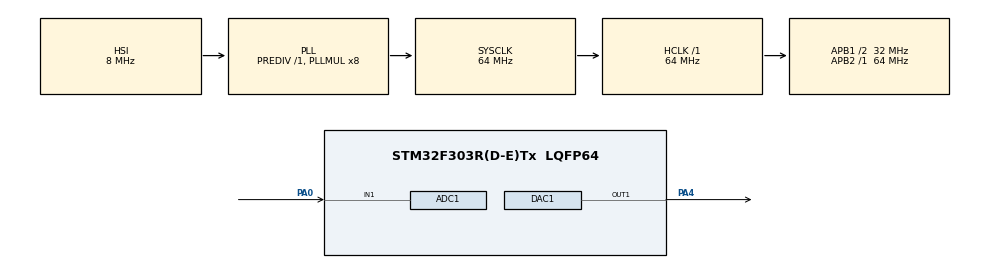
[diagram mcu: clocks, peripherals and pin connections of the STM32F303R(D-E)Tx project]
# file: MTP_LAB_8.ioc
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ADC1.Channel-5\#ChannelRegularConversion=ADC_CHANNEL_1
ADC1.Channel-6\#ChannelRegularConversion=ADC_CHANNEL_TEMPSENSOR
ADC1.Channel-7\#ChannelRegularConversion=ADC_CHANNEL_VREFINT
ADC1.ClockPrescaler=ADC_CLOCK_ASYNC_DIV1
ADC1.ContinuousConvMode=DISABLE
ADC1.DMAContinuousRequests=ENABLE
ADC1.EOCSelection=ADC_EOC_SINGLE_CONV
ADC1.EnableAnalogWatchDog1=false
ADC1.EnableInjectedConversion=DISABLE
ADC1.EnableRegularConversion=ENABLE
ADC1.ExternalTrigConv=ADC_EXTERNALTRIGCONV_T6_TRGO
ADC1.NbrOfConversion=3
ADC1.NbrOfConversionFlag=1
ADC1.Offset-5\#ChannelRegularConversion=0
ADC1.Offset-6\#ChannelRegularConversion=0
ADC1.Offset-7\#ChannelRegularConversion=0
ADC1.OffsetNumber-5\#ChannelRegularConversion=ADC_OFFSET_NONE
ADC1.OffsetNumber-6\#ChannelRegularConversion=ADC_OFFSET_NONE
ADC1.OffsetNumber-7\#ChannelRegularConversion=ADC_OFFSET_NONE
ADC1.Rank-5\#ChannelRegularConversion=1
ADC1.Rank-6\#ChannelRegularConversion=2
ADC1.Rank-7\#ChannelRegularConversion=3
ADC1.SamplingTime-5\#ChannelRegularConversion=ADC_SAMPLETIME_7CYCLES_5
ADC1.SamplingTime-6\#ChannelRegularConversion=ADC_SAMPLETIME_181CYCLES_5
ADC1.SamplingTime-7\#ChannelRegularConversion=ADC_SAMPLETIME_181CYCLES_5
ADC1.master=1
DAC1.DAC_Trigger=DAC_TRIGGER_T2_TRGO
Dma.ADC1.0.Direction=DMA_PERIPH_TO_MEMORY
Dma.ADC1.0.Instance=DMA1_Channel1
Dma.ADC1.0.MemDataAlignment=DMA_MDATAALIGN_WORD
Dma.ADC1.0.MemInc=DMA_MINC_ENABLE
Dma.ADC1.0.Mode=DMA_CIRCULAR
Dma.ADC1.0.PeriphDataAlignment=DMA_PDATAALIGN_WORD
Dma.ADC1.0.PeriphInc=DMA_PINC_DISABLE
Dma.ADC1.0.Priority=DMA_PRIORITY_VERY_HIGH
Dma.DAC1_CH1.1.Direction=DMA_MEMORY_TO_PERIPH
Dma.DAC1_CH1.1.Instance=DMA1_Channel3
Dma.DAC1_CH1.1.MemDataAlignment=DMA_MDATAALIGN_BYTE
Dma.DAC1_CH1.1.MemInc=DMA_MINC_ENABLE
Dma.DAC1_CH1.1.Mode=DMA_CIRCULAR
Dma.DAC1_CH1.1.PeriphDataAlignment=DMA_PDATAALIGN_BYTE
Dma.DAC1_CH1.1.PeriphInc=DMA_PINC_DISABLE
Dma.DAC1_CH1.1.Priority=DMA_PRIORITY_VERY_HIGH
Dma.Request0=ADC1
Dma.Request1=DAC1_CH1
Mcu.Family=STM32F3
Mcu.Name=STM32F303R(D-E)Tx
Mcu.Package=LQFP64
NVIC.DMA1_Channel1_IRQn=true\:0\:0\:false\:false\:true\:false\:true
NVIC.DMA1_Channel3_IRQn=true\:0\:0\:false\:false\:true\:false\:true
NVIC.PriorityGroup=NVIC_PRIORITYGROUP_4
NVIC.TIM2_IRQn=true\:0\:0\:false\:false\:true\:true\:true
PA0.Mode=IN1-Single-Ended
PA0.Signal=ADC1_IN1
PA13.Mode=Serial_Wire
PA13.Signal=SYS_JTMS-SWDIO
PA14.Mode=Serial_Wire
PA14.Signal=SYS_JTCK-SWCLK
PA4.Signal=COMP_DAC11_group
ProjectManager.HeapSize=0x200
ProjectManager.StackSize=0x400
ProjectManager.TargetToolchain=STM32CubeIDE
RCC.AHBFreq_Value=64000000
RCC.APB1CLKDivider=RCC_HCLK_DIV2
RCC.APB1Freq_Value=32000000
RCC.APB1TimFreq_Value=64000000
RCC.APB2Freq_Value=64000000
RCC.APB2TimFreq_Value=64000000
RCC.CortexFreq_Value=64000000
RCC.HCLKFreq_Value=64000000
RCC.HSE_VALUE=8000000
RCC.HSI_VALUE=8000000
RCC.LSE_VALUE=32768
RCC.PLLMUL=RCC_PLL_MUL8
RCC.SYSCLKFreq_VALUE=64000000
RCC.SYSCLKSourceVirtual=RCC_SYSCLKSOURCE_PLLCLK
RCC.USBFreq_Value=64000000
SH.COMP_DAC11_group.0=DAC1_OUT1,DAC_OUT1
TIM2.Period=999
TIM2.Prescaler=6399
TIM2.TIM_MasterOutputTrigger=TIM_TRGO_UPDATE
TIM6.Period=63
TIM6.Prescaler=0
TIM6.TIM_MasterOutputTrigger=TIM_TRGO_UPDATE
VP_ADC1_TempSens_Input.Mode=IN-TempSens
VP_ADC1_Vref_Input.Mode=IN-Vrefint
VP_TIM2_VS_ClockSourceINT.Mode=Internal
VP_TIM6_VS_ClockSourceINT.Mode=Enable_Timer
board=custom

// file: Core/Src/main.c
/* USER CODE BEGIN Header */
/**
  ******************************************************************************
  * @file           : main.c
  * @brief          : Main program body
  ******************************************************************************
  * @attention
  *
  * <h2><center>&copy; Copyright (c) 2021 STMicroelectronics.
  * All rights reserved.</center></h2>
  *
  * This software component is licensed by ST under BSD 3-Clause license,
  * the "License"; You may not use this file except in compliance with the
  * License. You may obtain a copy of the License at:
  *                        opensource.org/licenses/BSD-3-Clause
  *
  ******************************************************************************
  */
/* USER CODE END Header */

#include "main.h"

/* USER CODE BEGIN Includes */
#include <math.h>
#include <stdio.h>
/* USER CODE END Includes */

/* USER CODE BEGIN PTD */
typedef union
{
	struct {
		uint32_t usCh1;
		uint32_t usTemInt;
		uint32_t usVrefInt;
	};
	uint32_t usADCall[3];
} ADCData_t;
/* USER CODE END PTD */

void SystemClock_Config(void);
static void MX_GPIO_Init(void);
static void MX_DMA_Init(void);
static void MX_ADC1_Init(void);
static void MX_DAC1_Init(void);
static void MX_TIM2_Init(void);
static void MX_TIM6_Init(void);
/* USER CODE BEGIN PFP */

#define RESOLUTION	256.0

uint8_t ubSinValues[(int)RESOLUTION];
uint8_t sindex;

ADCData_t adcData;
uint32_t vref, vcalc, vtemp;
/* USER CODE END PFP */

int main(void)
{
  /* USER CODE BEGIN 1 */
  for (uint16_t i = 0; i < (int)RESOLUTION; i++) {
	  ubSinValues[i] = (uint8_t)((sin((double)M_PI*2.0*(double)i/RESOLUTION) * (double)0.5)*(double)(RESOLUTION));
  }
  /* USER CODE END 1 */

  /* MCU Configuration--------------------------------------------------------*/

  /* Reset of all peripherals, Initializes the Flash interface and the Systick. */
  HAL_Init();

  /* Configure the system clock */
  SystemClock_Config();

  /* Initialize all configured peripherals */
  MX_GPIO_Init();
  MX_DMA_Init();
  MX_ADC1_Init();
  MX_DAC1_Init();
  MX_TIM2_Init();
  MX_TIM6_Init();
  /* USER CODE BEGIN 2 */

  LL_DMA_SetMemoryAddress(DMA1, LL_DMA_CHANNEL_1, (uint32_t)&adcData);
  LL_DMA_SetDataLength(DMA1, LL_DMA_CHANNEL_1, 3);
  LL_DMA_SetPeriphAddress(DMA1, LL_DMA_CHANNEL_1, (uint32_t)&ADC1->DR);
  LL_DMA_EnableChannel(DMA1, LL_DMA_CHANNEL_1);

  LL_ADC_EnableInternalRegulator(ADC1);
  HAL_Delay(1);

  ADC12_COMMON->CCR |= ADC_CCR_TSEN | ADC_CCR_VREFEN;
  HAL_Delay(1);

  LL_ADC_StartCalibration(ADC1, LL_ADC_SINGLE_ENDED);
  while(LL_ADC_IsCalibrationOnGoing(ADC1));

  LL_ADC_REG_StartConversion(ADC1);
  LL_ADC_Enable(ADC1);

  LL_DMA_SetMemoryAddress(DMA1, LL_DMA_CHANNEL_3, (uint32_t)ubSinValues);
  LL_DMA_SetDataLength(DMA1, LL_DMA_CHANNEL_3, RESOLUTION);
  LL_DMA_SetPeriphAddress(DMA1, LL_DMA_CHANNEL_3, (uint32_t)&DAC1->DHR8R1);
  LL_DMA_EnableChannel(DMA1, LL_DMA_CHANNEL_3);

  LL_DAC_Enable(DAC1, LL_DAC_CHANNEL_1);
  LL_DAC_EnableDMAReq(DAC1, LL_DAC_CHANNEL_1);

  LL_TIM_EnableCounter(TIM2);
  LL_TIM_EnableCounter(TIM6);

  /* USER CODE END 2 */

  /* Infinite loop */
  /* USER CODE BEGIN WHILE */
  HAL_Delay(10); // wait load data otherwise hardfault
  while (1)
  {
	  vref = __LL_ADC_CALC_VREFANALOG_VOLTAGE((uint32_t)adcData.usVrefInt, LL_ADC_RESOLUTION_12B);
	  vcalc = __LL_ADC_CALC_DATA_TO_VOLTAGE(vref, (uint32_t)adcData.usCh1, LL_ADC_RESOLUTION_12B);
	  vtemp = __LL_ADC_CALC_TEMPERATURE(vref, (uint32_t)adcData.usTemInt, LL_ADC_RESOLUTION_12B);
    /* USER CODE END WHILE */

  }
}

void SystemClock_Config(void)
{
  RCC_OscInitTypeDef RCC_OscInitStruct = {0};
  RCC_ClkInitTypeDef RCC_ClkInitStruct = {0};
  RCC_PeriphCLKInitTypeDef PeriphClkInit = {0};

  /** Initializes the CPU, AHB and APB busses clocks
  */
  RCC_OscInitStruct.OscillatorType = RCC_OSCILLATORTYPE_HSI;
  RCC_OscInitStruct.HSIState = RCC_HSI_ON;
  RCC_OscInitStruct.HSICalibrationValue = RCC_HSICALIBRATION_DEFAULT;
  RCC_OscInitStruct.PLL.PLLState = RCC_PLL_ON;
  RCC_OscInitStruct.PLL.PLLSource = RCC_PLLSOURCE_HSI;
  RCC_OscInitStruct.PLL.PLLMUL = RCC_PLL_MUL8;
  RCC_OscInitStruct.PLL.PREDIV = RCC_PREDIV_DIV1;
  if (HAL_RCC_OscConfig(&RCC_OscInitStruct) != HAL_OK)
  {
    Error_Handler();
  }
  /** Initializes the CPU, AHB and APB busses clocks
  */
  RCC_ClkInitStruct.ClockType = RCC_CLOCKTYPE_HCLK|RCC_CLOCKTYPE_SYSCLK
                              |RCC_CLOCKTYPE_PCLK1|RCC_CLOCKTYPE_PCLK2;
  RCC_ClkInitStruct.SYSCLKSource = RCC_SYSCLKSOURCE_PLLCLK;
  RCC_ClkInitStruct.AHBCLKDivider = RCC_SYSCLK_DIV1;
  RCC_ClkInitStruct.APB1CLKDivider = RCC_HCLK_DIV2;
  RCC_ClkInitStruct.APB2CLKDivider = RCC_HCLK_DIV1;

  if (HAL_RCC_ClockConfig(&RCC_ClkInitStruct, FLASH_LATENCY_2) != HAL_OK)
  {
    Error_Handler();
  }
  PeriphClkInit.PeriphClockSelection = RCC_PERIPHCLK_ADC12|RCC_PERIPHCLK_TIM2;
  PeriphClkInit.Adc12ClockSelection = RCC_ADC12PLLCLK_DIV1;
  PeriphClkInit.Tim2ClockSelection = RCC_TIM2CLK_HCLK;
  if (HAL_RCCEx_PeriphCLKConfig(&PeriphClkInit) != HAL_OK)
  {
    Error_Handler();
  }
}

static void MX_ADC1_Init(void)
{

  LL_ADC_InitTypeDef ADC_InitStruct = {0};
  LL_ADC_REG_InitTypeDef ADC_REG_InitStruct = {0};
  LL_ADC_CommonInitTypeDef ADC_CommonInitStruct = {0};

  LL_GPIO_InitTypeDef GPIO_InitStruct = {0};

  /* Peripheral clock enable */
  LL_AHB1_GRP1_EnableClock(LL_AHB1_GRP1_PERIPH_ADC12);

  LL_AHB1_GRP1_EnableClock(LL_AHB1_GRP1_PERIPH_GPIOA);
  /**ADC1 GPIO Configuration
  PA0   ------> ADC1_IN1
  */
  GPIO_InitStruct.Pin = LL_GPIO_PIN_0;
  GPIO_InitStruct.Mode = LL_GPIO_MODE_ANALOG;
  GPIO_InitStruct.Pull = LL_GPIO_PULL_NO;
  LL_GPIO_Init(GPIOA, &GPIO_InitStruct);

  /* ADC1 DMA Init */

  /* ADC1 Init */
  LL_DMA_SetDataTransferDirection(DMA1, LL_DMA_CHANNEL_1, LL_DMA_DIRECTION_PERIPH_TO_MEMORY);

  LL_DMA_SetChannelPriorityLevel(DMA1, LL_DMA_CHANNEL_1, LL_DMA_PRIORITY_VERYHIGH);

  LL_DMA_SetMode(DMA1, LL_DMA_CHANNEL_1, LL_DMA_MODE_CIRCULAR);

  LL_DMA_SetPeriphIncMode(DMA1, LL_DMA_CHANNEL_1, LL_DMA_PERIPH_NOINCREMENT);

  LL_DMA_SetMemoryIncMode(DMA1, LL_DMA_CHANNEL_1, LL_DMA_MEMORY_INCREMENT);

  LL_DMA_SetPeriphSize(DMA1, LL_DMA_CHANNEL_1, LL_DMA_PDATAALIGN_WORD);

  LL_DMA_SetMemorySize(DMA1, LL_DMA_CHANNEL_1, LL_DMA_MDATAALIGN_WORD);

  /** Common config
  */
  ADC_InitStruct.Resolution = LL_ADC_RESOLUTION_12B;
  ADC_InitStruct.DataAlignment = LL_ADC_DATA_ALIGN_RIGHT;
  ADC_InitStruct.LowPowerMode = LL_ADC_LP_MODE_NONE;
  LL_ADC_Init(ADC1, &ADC_InitStruct);
  ADC_REG_InitStruct.TriggerSource = LL_ADC_REG_TRIG_EXT_TIM6_TRGO_ADC12;
  ADC_REG_InitStruct.SequencerLength = LL_ADC_REG_SEQ_SCAN_ENABLE_3RANKS;
  ADC_REG_InitStruct.SequencerDiscont = LL_ADC_REG_SEQ_DISCONT_DISABLE;
  ADC_REG_InitStruct.ContinuousMode = LL_ADC_REG_CONV_SINGLE;
  ADC_REG_InitStruct.DMATransfer = LL_ADC_REG_DMA_TRANSFER_UNLIMITED;
  ADC_REG_InitStruct.Overrun = LL_ADC_REG_OVR_DATA_OVERWRITTEN;
  LL_ADC_REG_Init(ADC1, &ADC_REG_InitStruct);
  LL_ADC_DisableIT_EOC(ADC1);
  LL_ADC_DisableIT_EOS(ADC1);
  ADC_CommonInitStruct.CommonClock = LL_ADC_CLOCK_ASYNC_DIV1;
  ADC_CommonInitStruct.Multimode = LL_ADC_MULTI_INDEPENDENT;
  LL_ADC_CommonInit(__LL_ADC_COMMON_INSTANCE(ADC1), &ADC_CommonInitStruct);
  LL_ADC_REG_SetTriggerEdge(ADC1, LL_ADC_REG_TRIG_EXT_RISING);
  /** Configure Regular Channel
  */
  LL_ADC_REG_SetSequencerRanks(ADC1, LL_ADC_REG_RANK_1, LL_ADC_CHANNEL_1);
  LL_ADC_SetChannelSamplingTime(ADC1, LL_ADC_CHANNEL_1, LL_ADC_SAMPLINGTIME_7CYCLES_5);
  LL_ADC_SetChannelSingleDiff(ADC1, LL_ADC_CHANNEL_1, LL_ADC_SINGLE_ENDED);
  /** Configure Regular Channel
  */
  LL_ADC_REG_SetSequencerRanks(ADC1, LL_ADC_REG_RANK_2, LL_ADC_CHANNEL_TEMPSENSOR);
  LL_ADC_SetChannelSamplingTime(ADC1, LL_ADC_CHANNEL_TEMPSENSOR, LL_ADC_SAMPLINGTIME_181CYCLES_5);
  LL_ADC_SetChannelSingleDiff(ADC1, LL_ADC_CHANNEL_TEMPSENSOR, LL_ADC_SINGLE_ENDED);
  LL_ADC_SetCommonPathInternalCh(__LL_ADC_COMMON_INSTANCE(ADC1), LL_ADC_PATH_INTERNAL_TEMPSENSOR);
  /** Configure Regular Channel
  */
  LL_ADC_REG_SetSequencerRanks(ADC1, LL_ADC_REG_RANK_3, LL_ADC_CHANNEL_VREFINT);
  LL_ADC_SetChannelSamplingTime(ADC1, LL_ADC_CHANNEL_VREFINT, LL_ADC_SAMPLINGTIME_181CYCLES_5);
  LL_ADC_SetChannelSingleDiff(ADC1, LL_ADC_CHANNEL_VREFINT, LL_ADC_SINGLE_ENDED);
  LL_ADC_SetCommonPathInternalCh(__LL_ADC_COMMON_INSTANCE(ADC1), LL_ADC_PATH_INTERNAL_VREFINT);

}

static void MX_DAC1_Init(void)
{

  LL_DAC_InitTypeDef DAC_InitStruct = {0};

  LL_GPIO_InitTypeDef GPIO_InitStruct = {0};

  /* Peripheral clock enable */
  LL_APB1_GRP1_EnableClock(LL_APB1_GRP1_PERIPH_DAC1);

  LL_AHB1_GRP1_EnableClock(LL_AHB1_GRP1_PERIPH_GPIOA);
  /**DAC1 GPIO Configuration
  PA4   ------> DAC1_OUT1
  */
  GPIO_InitStruct.Pin = LL_GPIO_PIN_4;
  GPIO_InitStruct.Mode = LL_GPIO_MODE_ANALOG;
  GPIO_InitStruct.Pull = LL_GPIO_PULL_NO;
  LL_GPIO_Init(GPIOA, &GPIO_InitStruct);

  /* DAC1 DMA Init */

  /* DAC1_CH1 Init */
  LL_DMA_SetDataTransferDirection(DMA1, LL_DMA_CHANNEL_3, LL_DMA_DIRECTION_MEMORY_TO_PERIPH);

  LL_DMA_SetChannelPriorityLevel(DMA1, LL_DMA_CHANNEL_3, LL_DMA_PRIORITY_VERYHIGH);

  LL_DMA_SetMode(DMA1, LL_DMA_CHANNEL_3, LL_DMA_MODE_CIRCULAR);

  LL_DMA_SetPeriphIncMode(DMA1, LL_DMA_CHANNEL_3, LL_DMA_PERIPH_NOINCREMENT);

  LL_DMA_SetMemoryIncMode(DMA1, LL_DMA_CHANNEL_3, LL_DMA_MEMORY_INCREMENT);

  LL_DMA_SetPeriphSize(DMA1, LL_DMA_CHANNEL_3, LL_DMA_PDATAALIGN_BYTE);

  LL_DMA_SetMemorySize(DMA1, LL_DMA_CHANNEL_3, LL_DMA_MDATAALIGN_BYTE);

  LL_SYSCFG_SetRemapDMA_DAC(LL_SYSCFG_DAC1_CH1_RMP_DMA1_CH3);

  /** DAC channel OUT1 config
  */
  DAC_InitStruct.TriggerSource = LL_DAC_TRIG_EXT_TIM2_TRGO;
  DAC_InitStruct.WaveAutoGeneration = LL_DAC_WAVE_AUTO_GENERATION_NONE;
  DAC_InitStruct.OutputBuffer = LL_DAC_OUTPUT_BUFFER_ENABLE;
  LL_DAC_Init(DAC1, LL_DAC_CHANNEL_1, &DAC_InitStruct);
  LL_DAC_EnableTrigger(DAC1, LL_DAC_CHANNEL_1);

}

static void MX_TIM2_Init(void)
{

  LL_TIM_InitTypeDef TIM_InitStruct = {0};

  /* Peripheral clock enable */
  LL_APB1_GRP1_EnableClock(LL_APB1_GRP1_PERIPH_TIM2);

  /* TIM2 interrupt Init */
  NVIC_SetPriority(TIM2_IRQn, NVIC_EncodePriority(NVIC_GetPriorityGrouping(),0, 0));
  NVIC_EnableIRQ(TIM2_IRQn);

  TIM_InitStruct.Prescaler = 6399;
  TIM_InitStruct.CounterMode = LL_TIM_COUNTERMODE_UP;
  TIM_InitStruct.Autoreload = 999;
  TIM_InitStruct.ClockDivision = LL_TIM_CLOCKDIVISION_DIV1;
  LL_TIM_Init(TIM2, &TIM_InitStruct);
  LL_TIM_DisableARRPreload(TIM2);
  LL_TIM_SetClockSource(TIM2, LL_TIM_CLOCKSOURCE_INTERNAL);
  LL_TIM_SetTriggerOutput(TIM2, LL_TIM_TRGO_UPDATE);
  LL_TIM_DisableMasterSlaveMode(TIM2);

}

static void MX_TIM6_Init(void)
{

  LL_TIM_InitTypeDef TIM_InitStruct = {0};

  /* Peripheral clock enable */
  LL_APB1_GRP1_EnableClock(LL_APB1_GRP1_PERIPH_TIM6);

  TIM_InitStruct.Prescaler = 0;
  TIM_InitStruct.CounterMode = LL_TIM_COUNTERMODE_UP;
  TIM_InitStruct.Autoreload = 63;
  LL_TIM_Init(TIM6, &TIM_InitStruct);
  LL_TIM_DisableARRPreload(TIM6);
  LL_TIM_SetTriggerOutput(TIM6, LL_TIM_TRGO_UPDATE);
  LL_TIM_DisableMasterSlaveMode(TIM6);

}

static void MX_DMA_Init(void)
{

  /* DMA controller clock enable */
  __HAL_RCC_DMA1_CLK_ENABLE();

  /* DMA interrupt init */
  /* DMA1_Channel1_IRQn interrupt configuration */
  NVIC_SetPriority(DMA1_Channel1_IRQn, NVIC_EncodePriority(NVIC_GetPriorityGrouping(),0, 0));
  NVIC_EnableIRQ(DMA1_Channel1_IRQn);
  /* DMA1_Channel3_IRQn interrupt configuration */
  NVIC_SetPriority(DMA1_Channel3_IRQn, NVIC_EncodePriority(NVIC_GetPriorityGrouping(),0, 0));
  NVIC_EnableIRQ(DMA1_Channel3_IRQn);

}

static void MX_GPIO_Init(void)
{

  /* GPIO Ports Clock Enable */
  __HAL_RCC_GPIOA_CLK_ENABLE();

}

void Error_Handler(void)
{
}

/************************ (C) COPYRIGHT STMicroelectronics *****END OF FILE****/
